# MB9B560L register map
File version: 1.3
MB9B560L Series
CPU: 
Registers are 8-bit, read-write, reset 0x0 unless marked. A register's access mark holds for its fields unless they carry their own. Offsets are from the block's base; lines under a group give offsets from that group; [hi:lo] are bit positions; {n}, {i} and the like mark numbered series; 'fields as' and 'values as' point back to an identical list; <NAME> marks a mode.

## Memory map
0x200E0000 WORKFLASH_IF size 0xC — WorkFlash Memory
0x40000000 FLASH_IF size 0xC — Flash Memory
0x40000200 UNIQUE_ID size 0x4
0x40000300 ECC_CAPTURE size 0x4 — ECC Capture Address
0x40010000 CRG size 0x70 — Clock Unit Registers
0x40011000 HWWDT size 0x4 — Hardware Watchdog Timer
0x40012000 SWWDT size 0x4 — Software Watchdog Timer
0x40015000 DTIM size 0x1C — Dual Timer
0x40020000 MFT0 size 0x1EC — Multifunction Timer 0
0x40021000 MFT1 size 0x1EC — Multifunction Timer 0
0x40024000 MFT_PPG size 0x2 — PPG Configuration
0x40025000 BT0 size 0x2 — Base Timer 0
0x40025040 BT1 size 0x2 — Base Timer 0
0x40025080 BT2 size 0x2 — Base Timer 0
0x400250C0 BT3 size 0x2 — Base Timer 0
0x40025100 BTIOSEL03 size 0x2 — Base Timer I/O Select
0x40025200 BT4 size 0x2 — Base Timer 0
0x40025240 BT5 size 0x2 — Base Timer 0
0x40025280 BT6 size 0x2 — Base Timer 0
0x400252C0 BT7 size 0x2 — Base Timer 0
0x40025300 BTIOSEL47 size 0x2 — Base Timer I/O Select
0x40025F00 SBSSR blocks up to offset 0xFE — Software-based Simultaneous Startup Register
0x40026000 QPRC0 size 0x2 — Quadrature Position/Revolution Counter 0
0x40026100 QPRC0_NF size 0x1 — Quadrature Position/Revolution Counter 0 Noise Filter
0x40027000 ADC0 size 0x2 — ADC0 Registers
0x40027100 ADC1 size 0x2 — ADC0 Registers
0x4002E000 CRTRIM size 0x1 — CR Trimming Registers
0x40030000 EXTI size 0x4 — External Interrupt and NMI Control
0x40031000 INTREQ size 0x4 — Interrupts
0x40033000 DAC0 size 0x1 — D/A Converter 0
0x40033008 DAC1 size 0x1 — D/A Converter 0
0x40035000 LVD size 0x1 — Low-voltage Detection
0x40035100 DS blocks up to offset 0x5 — Low Power Consumption Mode
0x40036000 USBCLK size 0x1 — USB/Ethernet Clock
0x40037000 CANPRES size 0x1 — CAN Prescaler Register
0x40038000 MFS0 size 0x2 — Multi-function Serial Interface 0
0x40038100 MFS1 size 0x2 — Multi-function Serial Interface 0
0x40038200 MFS2 size 0x2 — Multi-function Serial Interface 0
0x40038300 MFS3 size 0x2 — Multi-function Serial Interface 0
0x40038400 MFS4 size 0x2 — Multi-function Serial Interface 0
0x40038600 MFS6 size 0x2 — Multi-function Serial Interface 0
0x40039000 CRC size 0x1 — CRC Registers
0x4003A000 WC size 0x3 — Watch Counter
0x4003B000 RTC size 0x1B1 — REAL-TIME CLOCK
0x4003C000 LCR size 0x1 — Low-speed CR Prescaler
0x4003C100 CLK_GATING size 0x28 — Peripheral Clock Gating
0x4003C800 PLL_CONTROL size 0x8 — Main PLL Control
0x40040000 USB0 blocks up to offset 0x2102 — USB0 Function
0x40060000 DMAC size 0x4 — DMAC Registers
0x40061000 DSTC size 0xB0 — DSTC registers
0x40062000 CAN0 size 0xE — CAN0 Registers
0x4006F000 GPIO size 0x740 — 0

## Interrupts
0 CSV (CRG)
1 SWDT (SWWDT)
2 LVD
{n+11} EXINT{n} (EXTI) (n=0..7)
19 QPRC0
21 WFG0_DTIF0 (MFT0)
22 WFG1_DTIF1 (MFT1)
24 FRT0_PEAK (MFT0)
25 FRT0_ZERO (MFT0)
26 ICU0 (MFT0)
27 OCU0 (MFT0)
28 FRT1_PEAK (MFT1)
29 FRT1_ZERO (MFT1)
30 ICU1 (MFT1)
31 OCU1 (MFT1)
36 PPG00_02_04 (MFT_PPG)
37 PPG08_10_12 (MFT_PPG)
38 PPG16_18_20 (MFT_PPG)
{n+39} BT{n} (n=0..7)
47 DT1_2 (DTIM)
48 WC
50 RTC
{n+43} EXINT{n} (EXTI) (n=8..15)
59 TIM (CRG)
60 MFS0_RX (MFS0)
61 MFS0_TX (MFS0)
62 MFS1_RX (MFS1)
63 MFS1_TX (MFS1)
64 MFS2_RX (MFS2)
65 MFS2_TX (MFS2)
66 MFS3_RX (MFS3)
67 MFS3_TX (MFS3)
68 MFS4_RX (MFS4)
69 MFS4_TX (MFS4)
72 MFS6_RX (MFS6)
73 MFS6_TX (MFS6)
76 ADC0
77 ADC1
78 USB0
79 USB0_HOST (USB0)
80 CAN0
{n+83} DMAC{n} (DMAC) (n=0..7)
91 DSTC
92 EXINT16_17_18_19 (EXTI)
93 EXINT20_21_22_23 (EXTI)
94 EXINT24_25_26_27 (EXTI)
95 EXINT28_29_30_31 (EXTI)
119 FLASH (FLASH_IF)

## WORKFLASH_IF — WorkFlash Memory
Base 0x200E0000
0x00 WFASZR 32-bit reset 0x1 — WorkFlash Access Size Register
  [0] ASZ — WorkFlash Access Size
0x04 WFRWTR 32-bit reset 0x4 — WorkFlash Read Wait Register
  [2:0] RWT — Read Wait Cycle
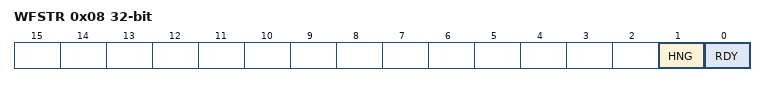
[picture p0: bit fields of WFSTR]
0x08 WFSTR 32-bit ro — WorkFlash Status Register
  [1] HNG — WorkFlash Hang
  [0] RDY — WorkFlash Rdy
